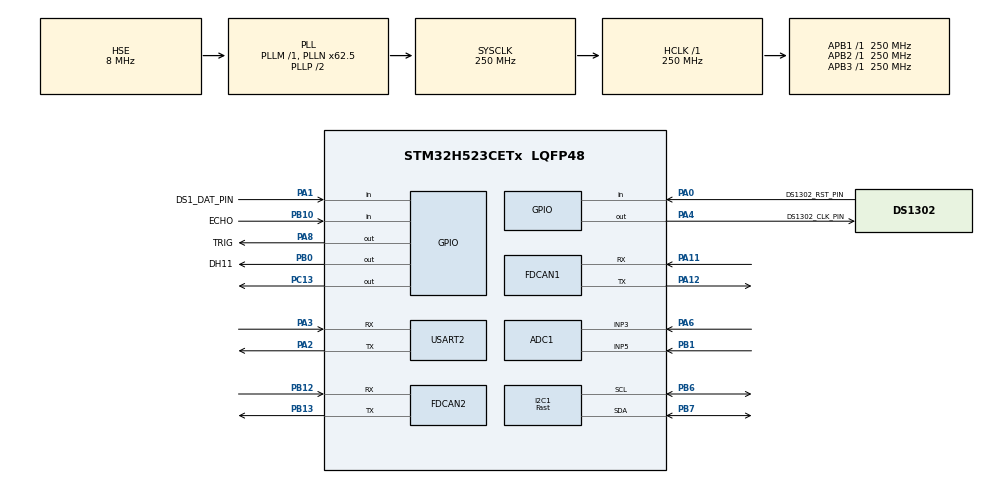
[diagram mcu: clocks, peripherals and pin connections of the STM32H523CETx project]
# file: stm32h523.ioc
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ADC1.Channel-0\#ChannelRegularConversion=ADC_CHANNEL_TEMPSENSOR
ADC1.DMAContinuousRequests=ENABLE
ADC1.MonitoredBy-0\#ChannelRegularConversion=__NULL
ADC1.NbrOfConversion=1
ADC1.NbrOfConversionFlag=1
ADC1.OffsetNumber-0\#ChannelRegularConversion=ADC_OFFSET_NONE
ADC1.Rank-0\#ChannelRegularConversion=1
ADC1.SamplingTime-0\#ChannelRegularConversion=ADC_SAMPLETIME_640CYCLES_5
ADC1.master=1
BOOTPATH.BootPathName=LEGACY
BOOTPATH.UserSelectedBootPath=LEGACY
CORTEX_M33_NS.Number-Cortex_Memory_Protection_Unit_Region0_OTP_RO_AREAS_Settings=MPU_REGION_NUMBER0
CORTEX_M33_NS.default_mode_Activation=1
CORTEX_M33_NS.userName=CORTEX_M33
FDCAN1.CalculateBaudRateNominal=166666
FDCAN1.CalculateTimeBitNominal=6000
FDCAN1.CalculateTimeQuantumNominal=2000.0
FDCAN2.CalculateBaudRateNominal=166666
FDCAN2.CalculateTimeBitNominal=6000
FDCAN2.CalculateTimeQuantumNominal=2000.0
GPDMA1.DESTDATAWIDTH_GPDMACH0=DMA_DEST_DATAWIDTH_HALFWORD
GPDMA1.DESTINC_GPDMACH0=DMA_DINC_INCREMENTED
GPDMA1.IPHANDLE_GPDMACH0-SIMPLEREQUEST_GPDMACH0=__NULL
GPDMA1.REQUEST_GPDMACH0=GPDMA1_REQUEST_ADC1
GPDMA1.SRCDATAWIDTH_GPDMACH0=DMA_SRC_DATAWIDTH_HALFWORD
I2C1.I2C_Speed_Mode=I2C_Fast
I2C1.Timing=0x10C043E5
Mcu.Family=STM32H5
Mcu.Name=STM32H523CETx
Mcu.Package=LQFP48
NVIC.ADC1_IRQn=true\:0\:0\:false\:false\:true\:true\:true\:true
NVIC.GPDMA1_Channel0_IRQn=true\:0\:0\:false\:false\:true\:true\:true\:true
NVIC.PriorityGroup=NVIC_PRIORITYGROUP_4
NVIC.TIM5_IRQn=true\:15\:0\:false\:false\:true\:false\:true\:true
NVIC.TimeBase=TIM5_IRQn
NVIC.TimeBaseIP=TIM5
NVIC.USART2_IRQn=true\:0\:0\:false\:false\:true\:true\:true\:true
PA0.GPIO_Label=DS1302_RST_PIN
PA0.GPIO_PuPd=GPIO_NOPULL
PA0.Signal=GPIO_Input
PA1.GPIO_Label=DS1_DAT_PIN
PA1.Signal=GPIO_Input
PA11.Mode=FDCAN_Activate
PA11.Signal=FDCAN1_RX
PA12.Mode=FDCAN_Activate
PA12.Signal=FDCAN1_TX
PA2.Mode=Asynchronous
PA2.Signal=USART2_TX
PA3.Mode=Asynchronous
PA3.Signal=USART2_RX
PA4.GPIO_Label=DS1302_CLK_PIN
PA4.Signal=GPIO_Output
PA6.Signal=ADCx_INP3
PA8.GPIO_Label=TRIG
PA8.Signal=GPIO_Output
PB0.GPIO_Label=DH11
PB0.Signal=GPIO_Output
PB1.Signal=ADCx_INP5
PB10.GPIO_Label=ECHO
PB10.Signal=GPIO_Input
PB12.Mode=FDCAN_Activate
PB12.Signal=FDCAN2_RX
PB13.Mode=FDCAN_Activate
PB13.Signal=FDCAN2_TX
PB6.Mode=I2C
PB6.Signal=I2C1_SCL
PB7.Mode=I2C
PB7.Signal=I2C1_SDA
PC13.Signal=GPIO_Output
PC14-OSC32_IN(OSC32_IN).Mode=LSE-External-Oscillator
PC14-OSC32_IN(OSC32_IN).Signal=RCC_OSC32_IN
PC15-OSC32_OUT(OSC32_OUT).Mode=LSE-External-Oscillator
PC15-OSC32_OUT(OSC32_OUT).Signal=RCC_OSC32_OUT
PH0-OSC_IN(PH0).Mode=HSE-External-Oscillator
PH0-OSC_IN(PH0).Signal=RCC_OSC_IN
PH1-OSC_OUT(PH1).Mode=HSE-External-Oscillator
PH1-OSC_OUT(PH1).Signal=RCC_OSC_OUT
ProjectManager.HeapSize=0x400
ProjectManager.StackSize=0x800
ProjectManager.TargetToolchain=CMake
RCC.ADCFreq_Value=250000000
RCC.AHBFreq_Value=250000000
RCC.APB1Freq_Value=250000000
RCC.APB1TimFreq_Value=250000000
RCC.APB2Freq_Value=250000000
RCC.APB2TimFreq_Value=250000000
RCC.APB3Freq_Value=250000000
RCC.CSI_VALUE=4000000
RCC.CortexFreq_Value=250000000
RCC.EPOD_VALUE=8000000
RCC.HCLKFreq_Value=250000000
RCC.HSE_VALUE=8000000
RCC.HSI48_VALUE=48000000
RCC.HSIDiv=RCC_HSI_DIV1
RCC.HSI_VALUE=64000000
RCC.LSIRC_VALUE=32000
RCC.PLL2FRACN=0
RCC.PLL2Source=RCC_PLL2_SOURCE_HSI
RCC.PLL3FRACN=0
RCC.PLL3Source=RCC_PLL3_SOURCE_HSI
RCC.PLLFRACN=4096
RCC.PLLN=62
RCC.PLLSourceVirtual=RCC_PLL1_SOURCE_HSE
RCC.SYSCLKFreq_VALUE=250000000
RCC.SYSCLKSource=RCC_SYSCLKSOURCE_PLLCLK
RCC.USBFreq_Value=48000000
RCC.VCOOutputFreq_Value=500000000
SH.ADCx_INP3.0=ADC1_INP3,IN3-Single-Ended
SH.ADCx_INP5.0=ADC1_INP5,IN5-Single-Ended
STMicroelectronics.X-CUBE-FREERTOS.1.6.0.configUSE_NEWLIB_REENTRANT=1
USART2.VirtualMode-Asynchronous=VM_ASYNC
VP_ADC1_TempSens_Input.Mode=IN-TempSens
VP_BOOTPATH_VS_BOOTPATH.Mode=BP_Activate
VP_CORTEX_M33_NS_VS_Ext.Mode=External_Mode
VP_GPDMA1_VS_GPDMACH0.Mode=SIMPLEREQUEST_GPDMACH0
VP_ICACHE_VS_ICACHE.Mode=DirectMappedCache
VP_MEMORYMAP_VS_MEMORYMAP.Mode=CurAppReg
VP_PWR_VS_LPOM.Mode=PowerOptimisation
VP_PWR_VS_SECSignals.Mode=Security/Privilege
VP_SYS_VS_tim5.Mode=TIM5
board=custom

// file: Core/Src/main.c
/* USER CODE BEGIN Header */
/**
  ******************************************************************************
  * @file           : main.c
  * @brief          : Main program body
  ******************************************************************************
  * @attention
  *
  * Copyright (c) 2026 STMicroelectronics.
  * All rights reserved.
  *
  * This software is licensed under terms that can be found in the LICENSE file
  * in the root directory of this software component.
  * If no LICENSE file comes with this software, it is provided AS-IS.
  *
  ******************************************************************************
  */
/* USER CODE END Header */
#include "main.h"
#include "adc.h"
#include "fdcan.h"
#include "gpdma.h"
#include "i2c.h"
#include "icache.h"
#include "usart.h"
#include "gpio.h"

/* USER CODE BEGIN Includes */
#include "apInit.h"
#include "apMain.h"
/* USER CODE END Includes */

void SystemClock_Config(void);
static void MPU_Config(void);

int main(void)
{

  /* MCU Configuration--------------------------------------------------------*/

  /* MPU Configuration--------------------------------------------------------*/
  MPU_Config();

  /* Reset of all peripherals, Initializes the Flash interface and the Systick. */
  HAL_Init();

  /* Configure the system clock */
  SystemClock_Config();

  /* Initialize all configured peripherals */
  MX_GPIO_Init();
  MX_GPDMA1_Init();
  MX_ICACHE_Init();
  MX_USART2_UART_Init();
  MX_ADC1_Init();
  MX_FDCAN1_Init();
  MX_I2C1_Init();
  MX_FDCAN2_Init();
  /* USER CODE BEGIN 2 */
  apInit();
  apMain();
  /* USER CODE END 2 */

  /* Infinite loop */
  while (1)
  {

  }
}

void SystemClock_Config(void)
{
  RCC_OscInitTypeDef RCC_OscInitStruct = {0};
  RCC_ClkInitTypeDef RCC_ClkInitStruct = {0};

  /** Configure the main internal regulator output voltage
  */
  __HAL_PWR_VOLTAGESCALING_CONFIG(PWR_REGULATOR_VOLTAGE_SCALE0);

  while(!__HAL_PWR_GET_FLAG(PWR_FLAG_VOSRDY)) {}

  /** Initializes the RCC Oscillators according to the specified parameters
  * in the RCC_OscInitTypeDef structure.
  */
  RCC_OscInitStruct.OscillatorType = RCC_OSCILLATORTYPE_HSE;
  RCC_OscInitStruct.HSEState = RCC_HSE_ON;
  RCC_OscInitStruct.PLL.PLLState = RCC_PLL_ON;
  RCC_OscInitStruct.PLL.PLLSource = RCC_PLL1_SOURCE_HSE;
  RCC_OscInitStruct.PLL.PLLM = 1;
  RCC_OscInitStruct.PLL.PLLN = 62;
  RCC_OscInitStruct.PLL.PLLP = 2;
  RCC_OscInitStruct.PLL.PLLQ = 2;
  RCC_OscInitStruct.PLL.PLLR = 2;
  RCC_OscInitStruct.PLL.PLLRGE = RCC_PLL1_VCIRANGE_3;
  RCC_OscInitStruct.PLL.PLLVCOSEL = RCC_PLL1_VCORANGE_WIDE;
  RCC_OscInitStruct.PLL.PLLFRACN = 4096;
  if (HAL_RCC_OscConfig(&RCC_OscInitStruct) != HAL_OK)
  {
    Error_Handler();
  }

  /** Initializes the CPU, AHB and APB buses clocks
  */
  RCC_ClkInitStruct.ClockType = RCC_CLOCKTYPE_HCLK|RCC_CLOCKTYPE_SYSCLK
                              |RCC_CLOCKTYPE_PCLK1|RCC_CLOCKTYPE_PCLK2
                              |RCC_CLOCKTYPE_PCLK3;
  RCC_ClkInitStruct.SYSCLKSource = RCC_SYSCLKSOURCE_PLLCLK;
  RCC_ClkInitStruct.AHBCLKDivider = RCC_SYSCLK_DIV1;
  RCC_ClkInitStruct.APB1CLKDivider = RCC_HCLK_DIV1;
  RCC_ClkInitStruct.APB2CLKDivider = RCC_HCLK_DIV1;
  RCC_ClkInitStruct.APB3CLKDivider = RCC_HCLK_DIV1;

  if (HAL_RCC_ClockConfig(&RCC_ClkInitStruct, FLASH_LATENCY_5) != HAL_OK)
  {
    Error_Handler();
  }

   /* Select SysTick source clock */
  HAL_SYSTICK_CLKSourceConfig(SYSTICK_CLKSOURCE_HCLK);

   /* Re-Initialize Tick with new clock source */
  if (HAL_InitTick(TICK_INT_PRIORITY) != HAL_OK)
  {
    Error_Handler();
  }

  /** Configure the programming delay
  */
  __HAL_FLASH_SET_PROGRAM_DELAY(FLASH_PROGRAMMING_DELAY_2);
}

 /* MPU Configuration */

void MPU_Config(void)
{
  MPU_Region_InitTypeDef MPU_InitStruct = {0};
  MPU_Attributes_InitTypeDef MPU_AttributesInit = {0};

  /* Disables the MPU */
  HAL_MPU_Disable();

  /** Initializes and configures the Region 0 and the memory to be protected
  */
  MPU_InitStruct.Enable = MPU_REGION_ENABLE;
  MPU_InitStruct.Number = MPU_REGION_NUMBER0;
  MPU_InitStruct.BaseAddress = 0x08FFF000;
  MPU_InitStruct.LimitAddress = 0x08FFFFFF;
  MPU_InitStruct.AttributesIndex = MPU_ATTRIBUTES_NUMBER0;
  MPU_InitStruct.AccessPermission = MPU_REGION_ALL_RO;
  MPU_InitStruct.DisableExec = MPU_INSTRUCTION_ACCESS_DISABLE;
  MPU_InitStruct.IsShareable = MPU_ACCESS_NOT_SHAREABLE;

  HAL_MPU_ConfigRegion(&MPU_InitStruct);

  /** Initializes and configures the Attribute 0 and the memory to be protected
  */
  MPU_AttributesInit.Number = MPU_ATTRIBUTES_NUMBER0;
  MPU_AttributesInit.Attributes = INNER_OUTER(MPU_NOT_CACHEABLE);

  HAL_MPU_ConfigMemoryAttributes(&MPU_AttributesInit);
  /* Enables the MPU */
  HAL_MPU_Enable(MPU_PRIVILEGED_DEFAULT);

}

void HAL_TIM_PeriodElapsedCallback(TIM_HandleTypeDef *htim)
{
  if (htim->Instance == TIM5)
  {
    HAL_IncTick();
  }
}

void Error_Handler(void)
{
  __disable_irq();
  while (1)
  {
  }
}
